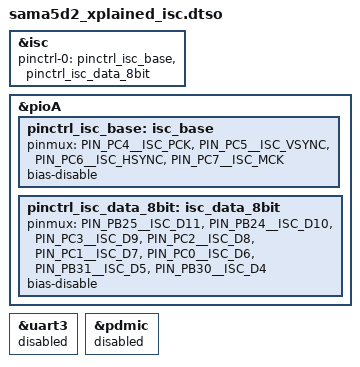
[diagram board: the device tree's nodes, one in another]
// SPDX-License-Identifier: (GPL-2.0+ OR MIT)
/*
 * Device Tree file for SAMA5D2 Xplained board
 * overlay blob for Image Sensor Controller.
 *
 * Copyright (C) 2018 Microchip Technology, Inc.
 * Author: Eugen Hristev <eugen.hristev@microchip.com>
 *
 */
/dts-v1/;
/plugin/;

#include "sama5d2-pinfunc.h"
#include <dt-bindings/gpio/gpio.h>

&isc {
	pinctrl-names = "default";
	pinctrl-0 = <&pinctrl_isc_base &pinctrl_isc_data_8bit>;
	status = "okay";
};

&pioA {
	pinctrl_isc_base: isc_base {
		pinmux = <PIN_PC4__ISC_PCK>,
			 <PIN_PC5__ISC_VSYNC>,
			 <PIN_PC6__ISC_HSYNC>,
			 <PIN_PC7__ISC_MCK>;
		bias-disable;
	};

	pinctrl_isc_data_8bit: isc_data_8bit {
		pinmux = <PIN_PB25__ISC_D11>,
			 <PIN_PB24__ISC_D10>,
			 <PIN_PC3__ISC_D9>,
			 <PIN_PC2__ISC_D8>,
			 <PIN_PC1__ISC_D7>,
			 <PIN_PC0__ISC_D6>,
			 <PIN_PB31__ISC_D5>,
			 <PIN_PB30__ISC_D4>;
		bias-disable;
	};
};

&uart3 {
		status = "disabled"; /* conflict on pin, disabling */
};

&pdmic {
		status = "disabled"; /* conflict on pin, disabling */
};
